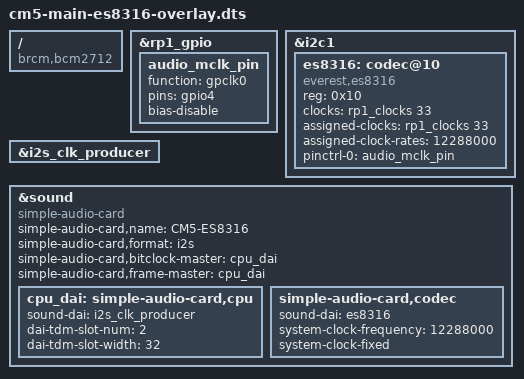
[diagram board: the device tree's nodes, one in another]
/dts-v1/;
/plugin/;
/ {
 compatible = "brcm,bcm2712";
 fragment@0 { target = <&rp1_gpio>; __overlay__ {
  audio_mclk_pin: audio_mclk_pin { function = "gpclk0"; pins = "gpio4"; bias-disable; };
 }; };
 fragment@1 { target = <&i2c1>; __overlay__ {
  #address-cells = <1>; #size-cells = <0>; status = "okay";
  es8316: codec@10 {
   compatible = "everest,es8316"; reg = <0x10>; #sound-dai-cells = <0>;
   clocks = <&rp1_clocks 33>; clock-names = "mclk";
   assigned-clocks = <&rp1_clocks 33>;
   assigned-clock-rates = <12288000>;
   pinctrl-names = "default"; pinctrl-0 = <&audio_mclk_pin>;
  };
 }; };
 fragment@2 { target = <&i2s_clk_producer>; __overlay__ { status = "okay"; }; };
 fragment@3 { target = <&sound>; __overlay__ {
  compatible = "simple-audio-card";
  status = "okay";
  simple-audio-card,name = "CM5-ES8316";
  simple-audio-card,format = "i2s";
  simple-audio-card,bitclock-master = <&cpu_dai>;
  simple-audio-card,frame-master = <&cpu_dai>;
  cpu_dai: simple-audio-card,cpu {
   sound-dai = <&i2s_clk_producer>;
   dai-tdm-slot-num = <2>; dai-tdm-slot-width = <32>;
  };
  simple-audio-card,codec {
   sound-dai = <&es8316>;
   system-clock-frequency = <12288000>;
   system-clock-fixed;
  };
 }; };
};
